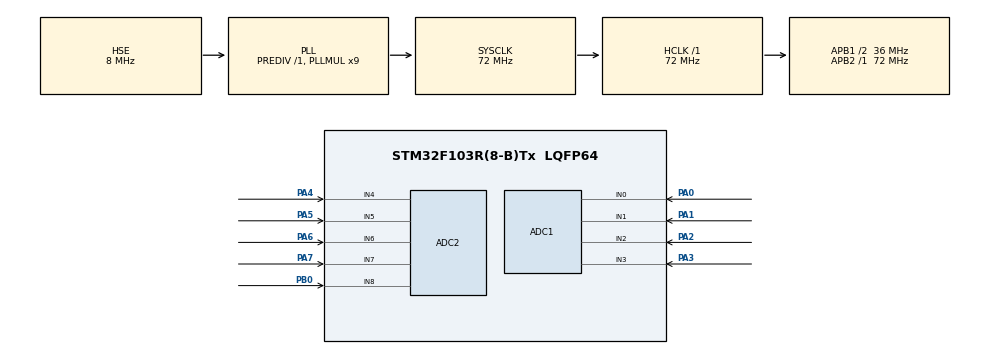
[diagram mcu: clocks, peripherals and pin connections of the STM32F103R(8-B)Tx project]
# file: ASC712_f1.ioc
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ADC1.Channel-0\#ChannelRegularConversion=ADC_CHANNEL_0
ADC1.Channel-1\#ChannelRegularConversion=ADC_CHANNEL_0
ADC1.Channel-2\#ChannelRegularConversion=ADC_CHANNEL_0
ADC1.Channel-3\#ChannelRegularConversion=ADC_CHANNEL_0
ADC1.DiscontinuousConvMode=ENABLE
ADC1.ExternalTrigConv=ADC_SOFTWARE_START
ADC1.NbrOfConversion=4
ADC1.NbrOfConversionFlag=1
ADC1.Rank-0\#ChannelRegularConversion=1
ADC1.Rank-1\#ChannelRegularConversion=2
ADC1.Rank-2\#ChannelRegularConversion=3
ADC1.Rank-3\#ChannelRegularConversion=4
ADC1.SamplingTime-0\#ChannelRegularConversion=ADC_SAMPLETIME_1CYCLE_5
ADC1.SamplingTime-1\#ChannelRegularConversion=ADC_SAMPLETIME_1CYCLE_5
ADC1.SamplingTime-2\#ChannelRegularConversion=ADC_SAMPLETIME_1CYCLE_5
ADC1.SamplingTime-3\#ChannelRegularConversion=ADC_SAMPLETIME_1CYCLE_5
ADC1.master=1
ADC2.Channel-1\#ChannelRegularConversion=ADC_CHANNEL_4
ADC2.Channel-2\#ChannelRegularConversion=ADC_CHANNEL_4
ADC2.Channel-3\#ChannelRegularConversion=ADC_CHANNEL_4
ADC2.Channel-4\#ChannelRegularConversion=ADC_CHANNEL_4
ADC2.Channel-5\#ChannelRegularConversion=ADC_CHANNEL_4
ADC2.DiscontinuousConvMode=ENABLE
ADC2.ExternalTrigConv=ADC_SOFTWARE_START
ADC2.NbrOfConversion=5
ADC2.NbrOfConversionFlag=1
ADC2.Rank-1\#ChannelRegularConversion=1
ADC2.Rank-2\#ChannelRegularConversion=2
ADC2.Rank-3\#ChannelRegularConversion=3
ADC2.Rank-4\#ChannelRegularConversion=4
ADC2.Rank-5\#ChannelRegularConversion=5
ADC2.SamplingTime-1\#ChannelRegularConversion=ADC_SAMPLETIME_1CYCLE_5
ADC2.SamplingTime-2\#ChannelRegularConversion=ADC_SAMPLETIME_1CYCLE_5
ADC2.SamplingTime-3\#ChannelRegularConversion=ADC_SAMPLETIME_1CYCLE_5
ADC2.SamplingTime-4\#ChannelRegularConversion=ADC_SAMPLETIME_1CYCLE_5
ADC2.SamplingTime-5\#ChannelRegularConversion=ADC_SAMPLETIME_1CYCLE_5
Mcu.Family=STM32F1
Mcu.Name=STM32F103R(8-B)Tx
Mcu.Package=LQFP64
NVIC.PriorityGroup=NVIC_PRIORITYGROUP_4
PA0-WKUP.Signal=ADCx_IN0
PA1.Signal=ADCx_IN1
PA13.Mode=Serial_Wire
PA13.Signal=SYS_JTMS-SWDIO
PA14.Mode=Serial_Wire
PA14.Signal=SYS_JTCK-SWCLK
PA2.Signal=ADCx_IN2
PA3.Signal=ADCx_IN3
PA4.Signal=ADCx_IN4
PA5.Signal=ADCx_IN5
PA6.Signal=ADCx_IN6
PA7.Signal=ADCx_IN7
PB0.Signal=ADCx_IN8
PD0-OSC_IN.Mode=HSE-External-Oscillator
PD0-OSC_IN.Signal=RCC_OSC_IN
PD1-OSC_OUT.Mode=HSE-External-Oscillator
PD1-OSC_OUT.Signal=RCC_OSC_OUT
ProjectManager.HeapSize=0x200
ProjectManager.StackSize=0x400
ProjectManager.TargetToolchain=STM32CubeIDE
RCC.ADCPresc=RCC_ADCPCLK2_DIV6
RCC.AHBFreq_Value=72000000
RCC.APB1CLKDivider=RCC_HCLK_DIV2
RCC.APB1Freq_Value=36000000
RCC.APB1TimFreq_Value=72000000
RCC.APB2Freq_Value=72000000
RCC.APB2TimFreq_Value=72000000
RCC.HCLKFreq_Value=72000000
RCC.PLLMUL=RCC_PLL_MUL9
RCC.PLLSourceVirtual=RCC_PLLSOURCE_HSE
RCC.SYSCLKFreq_VALUE=72000000
RCC.SYSCLKSource=RCC_SYSCLKSOURCE_PLLCLK
RCC.USBFreq_Value=72000000
SH.ADCx_IN0.0=ADC1_IN0,IN0
SH.ADCx_IN1.0=ADC1_IN1,IN1
SH.ADCx_IN2.0=ADC1_IN2,IN2
SH.ADCx_IN3.0=ADC1_IN3,IN3
SH.ADCx_IN4.0=ADC2_IN4,IN4
SH.ADCx_IN5.0=ADC2_IN5,IN5
SH.ADCx_IN6.0=ADC2_IN6,IN6
SH.ADCx_IN7.0=ADC2_IN7,IN7
SH.ADCx_IN8.0=ADC2_IN8,IN8
board=custom

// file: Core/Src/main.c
/* USER CODE BEGIN Header */
/**
  ******************************************************************************
  * @file           : main.c
  * @brief          : Main program body
  ******************************************************************************
  * @attention
  *
  * Copyright (c) 2022 STMicroelectronics.
  * All rights reserved.
  *
  * This software is licensed under terms that can be found in the LICENSE file
  * in the root directory of this software component.
  * If no LICENSE file comes with this software, it is provided AS-IS.
  *
  ******************************************************************************
  */
/* USER CODE END Header */
#include "main.h"
#include "adc.h"
#include "gpio.h"

/* USER CODE BEGIN Includes */
#include "asc712.h"
#include <stdio.h>
/* USER CODE END Includes */

void SystemClock_Config(void);

int main(void)
{

  /* MCU Configuration--------------------------------------------------------*/

  /* Reset of all peripherals, Initializes the Flash interface and the Systick. */
  HAL_Init();

  /* Configure the system clock */
  SystemClock_Config();

  /* Initialize all configured peripherals */
  MX_GPIO_Init();
  MX_ADC1_Init();
  MX_ADC2_Init();
  /* USER CODE BEGIN 2 */
  HAL_ADCEx_Calibration_Start(&hadc1);
  /* USER CODE END 2 */

  /* Infinite loop */
  while (1)
  {

    /* USER CODE BEGIN 3 */
	  survey_adc1_channel_IN0;
	  survey_adc1_channel_IN1;
	  survey_adc1_channel_IN2;
	  survey_adc1_channel_IN3;
	  survey_adc2_channel_IN4;
	  survey_adc2_channel_IN5;
	  survey_adc2_channel_IN6;
	  survey_adc2_channel_IN7;
	  survey_adc2_channel_IN8;
  }
  /* USER CODE END 3 */
}

void SystemClock_Config(void)
{
  RCC_OscInitTypeDef RCC_OscInitStruct = {0};
  RCC_ClkInitTypeDef RCC_ClkInitStruct = {0};
  RCC_PeriphCLKInitTypeDef PeriphClkInit = {0};

  /** Initializes the RCC Oscillators according to the specified parameters
  * in the RCC_OscInitTypeDef structure.
  */
  RCC_OscInitStruct.OscillatorType = RCC_OSCILLATORTYPE_HSE;
  RCC_OscInitStruct.HSEState = RCC_HSE_ON;
  RCC_OscInitStruct.HSEPredivValue = RCC_HSE_PREDIV_DIV1;
  RCC_OscInitStruct.HSIState = RCC_HSI_ON;
  RCC_OscInitStruct.PLL.PLLState = RCC_PLL_ON;
  RCC_OscInitStruct.PLL.PLLSource = RCC_PLLSOURCE_HSE;
  RCC_OscInitStruct.PLL.PLLMUL = RCC_PLL_MUL9;
  if (HAL_RCC_OscConfig(&RCC_OscInitStruct) != HAL_OK)
  {
    Error_Handler();
  }

  /** Initializes the CPU, AHB and APB buses clocks
  */
  RCC_ClkInitStruct.ClockType = RCC_CLOCKTYPE_HCLK|RCC_CLOCKTYPE_SYSCLK
                              |RCC_CLOCKTYPE_PCLK1|RCC_CLOCKTYPE_PCLK2;
  RCC_ClkInitStruct.SYSCLKSource = RCC_SYSCLKSOURCE_PLLCLK;
  RCC_ClkInitStruct.AHBCLKDivider = RCC_SYSCLK_DIV1;
  RCC_ClkInitStruct.APB1CLKDivider = RCC_HCLK_DIV2;
  RCC_ClkInitStruct.APB2CLKDivider = RCC_HCLK_DIV1;

  if (HAL_RCC_ClockConfig(&RCC_ClkInitStruct, FLASH_LATENCY_2) != HAL_OK)
  {
    Error_Handler();
  }
  PeriphClkInit.PeriphClockSelection = RCC_PERIPHCLK_ADC;
  PeriphClkInit.AdcClockSelection = RCC_ADCPCLK2_DIV6;
  if (HAL_RCCEx_PeriphCLKConfig(&PeriphClkInit) != HAL_OK)
  {
    Error_Handler();
  }
}

void Error_Handler(void)
{
  __disable_irq();
  while (1)
  {
  }
}
